# nrf9230_enga_cellcore register map
Vendor: Nordic Semiconductor; Series: nRF92; File version: 1
CPU: CM33 r0p4, little endian, MPU, FPU, 3 interrupt priority bits, 480 interrupts, 8 SAU regions
Registers are 32-bit, read-write, reset 0x0 unless marked. A register's access mark holds for its fields unless they carry their own. Offsets are from the block's base; [hi:lo] are bit positions; {n}, {i} and the like mark numbered series.

## TIMEREVENTSYNCH_NS — Timer event synchronizer 0
Base 0x44024000
Same registers: TIMEREVENTSYNCH_S 0x54024000
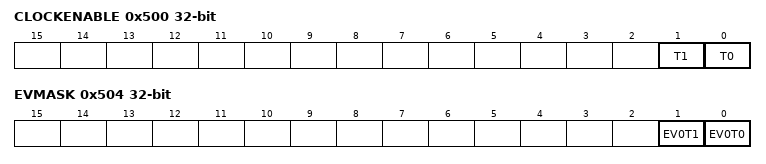
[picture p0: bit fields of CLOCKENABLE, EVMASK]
0x500 CLOCKENABLE — Enable synchronizer clock
  [1] T1 — Enable for clock ck_t1
    0=Disable clock ck_t1; 1=Enable clock ck_t1
  [0] T0 — Enable for clock ck_t0
    0=Disable clock ck_t0; 1=Enable clock ck_t0
0x504 EVMASK — Event mask
  [1] EV0T1 — Mask control for event 0 and output t1
    0=Disable (Event 0 is not propagated to output t1); 1=Enable (Event 0 is propagated to output t1)
  [0] EV0T0 — Mask control for event 0 and output t0
    0=Disable (Event 0 is not propagated to output t0); 1=Enable (Event 0 is propagated to output t0)

## TIMEMARKMUX0_NS — Timemark multiplexer 0
Base 0x44025000
Same registers: TIMEMARKMUX1_NS 0x44034000, TIMEMARKMUX2_NS 0x44038000, TIMEMARKMUX0_S 0x54025000, TIMEMARKMUX1_S 0x54034000, TIMEMARKMUX2_S 0x54038000
0x500 OUTPUTENABLE — Enable Timemark Mux
  [0] ENABLE
    0=Disable timemark output; 1=Enable timemark output
0x504 TIMEMARKSELECT — Timemark input select register
  [7:0] TIMEMARKSELECT — Timemark input select
    1=Event0 (Enable compareEventsIn[0] as timemark input); 2=Event1 (Enable compareEventsIn[1] as timemark input); 4=Event2 (Enable compareEventsIn[2] as timemark input); 8=Event3 (Enable compareEventsIn[3] as timemark input); 16=Event4 (Enable compareEventsIn[4] as timemark input); 32=Event5 (Enable compareEventsIn[5] as timemark input); 64=Event6 (Enable compareEventsIn[6] as timemark input); 128=Event7 (Enable compareEventsIn[7] as timemark input)

## CELLCORETIMERPDCTRL_NS — Cellular core TIMERPD FSM control
Base 0x54036500; alternate view of PCGCS3_S
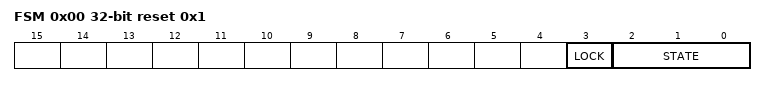
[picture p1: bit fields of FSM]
0x00 FSM reset 0x1 — Timer power domain finite state machine control
  [3] LOCK — Lock the state of TIMERFSM.
    0=UNLOCKED (FSM not locked.); 1=LOCKED (FSM locked.)
  [2:0] STATE — TIMERFSM state
    0=GUARD_TIMERPD_BRIDGE (Power requested for PD_TIMERS_ACT. Intermediate state between MCPLL_OFF and TIMERPD_GOING_OFF.); 1=TIMERPD_RESET (Power requested for PD_TIMERS_ACT. State after power domain reset.); 2=TIMERPD_GOING_ON (Power requested for PD_TIMERS_ACT. PD_TIMERS_ACT powering up. Intermediate state before MCPLL_OFF.); 3=MCPLL_ON (Power requested for PD_TIMERS_ACT. MCPLL clock requested.); 4=MCPLL_OFF (Power requested for PD_TIMERS_ACT. MCPLL clock not requested.); 5=TIMERPD_GOING_OFF (Power requested for PD_TIMERS_ACT. Intermediate state before TIMERPD_OFF.); 6=TIMERPD_OFF (No power requested for PD_TIMERS_ACT.)

## SWI0_NS — Software interrupt 0
Base 0x42058000
Same registers: SWI1_NS 0x42059000, SWI2_NS 0x4205A000, SWI3_NS 0x4205B000, SWI4_NS 0x4205C000, SWI5_NS 0x4205D000, SWI6_NS 0x4205E000, SWI7_NS 0x4205F000

## BELLBOARD_NS — BELLBOARD APB registers 0
Base 0x4F09C000
Same registers: BELLBOARD_S 0x5F09C000
{0x0+4i} TASKS_TRIGGER[{i}] (i=0..31) wo — Description collection: Task TRIGGER[n]
  [0] TASKS_TRIGGER — Task TRIGGER[n]
    1=Trigger task
{0x100+4i} EVENTS_TRIGGERED[{i}] (i=0..31) — Description collection: Event TRIGGERED[n]
  [0] EVENTS_TRIGGERED — Event TRIGGERED[n]
    0=NotGenerated (Event not generated); 1=Generated (Event generated)
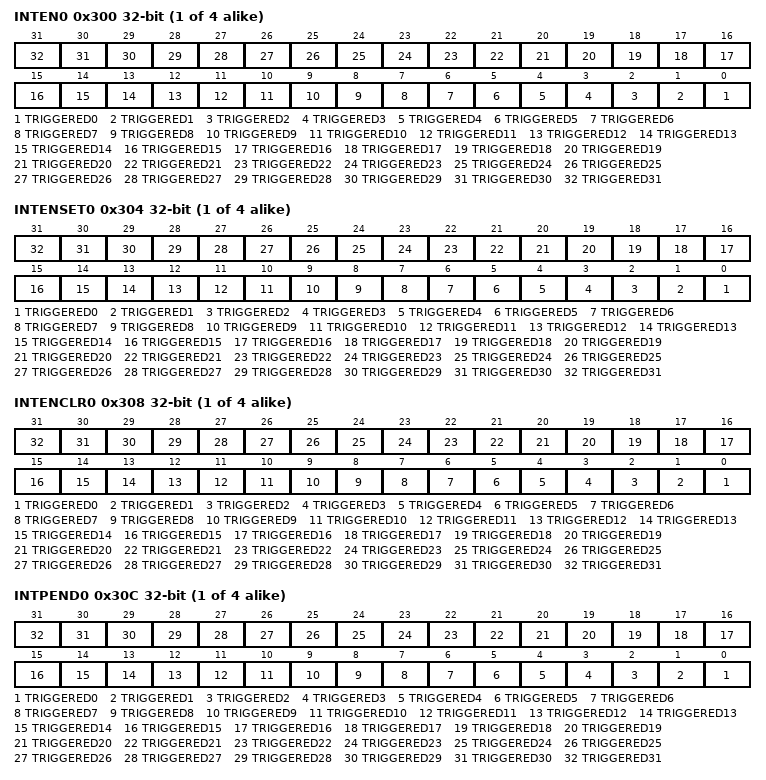
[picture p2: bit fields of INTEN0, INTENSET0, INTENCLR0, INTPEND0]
{0x300+0x10*i} INTEN{i} (i=0..3) — Enable or disable interrupt
  [all] fields
    0=Disabled; 1=Enabled
  [n] TRIGGERED{n} (n=0..31) — Enable or disable interrupt for event TRIGGERED[{n}]
{0x304+0x10*i} INTENSET{i} (i=0..3) — Enable interrupt
  [all] fields
    on read: 0=Disabled (Read: Disabled); 1=Enabled (Read: Enabled) | on write: 1=Set (Enable)
  [n] TRIGGERED{n} (n=0..31) — Write '1' to enable interrupt for event TRIGGERED[{n}]
{0x308+0x10*i} INTENCLR{i} (i=0..3) — Disable interrupt
  [all] fields
    on read: 0=Disabled (Read: Disabled); 1=Enabled (Read: Enabled) | on write: 1=Clear (Disable)
  [n] TRIGGERED{n} (n=0..31) — Write '1' to disable interrupt for event TRIGGERED[{n}]
{0x30C+0x10*i} INTPEND{i} ro (i=0..3) — Pending interrupts
  [all] fields
    on read: 0=NotPending (Read: Not pending); 1=Pending (Read: Pending)
  [n] TRIGGERED{n} (n=0..31) — Read pending status of interrupt for event TRIGGERED[{n}]
